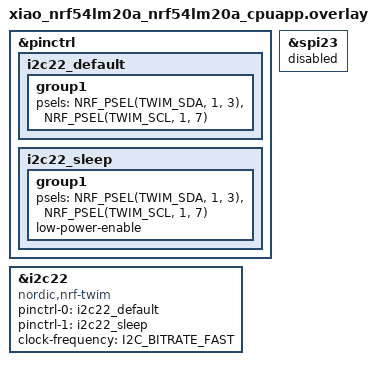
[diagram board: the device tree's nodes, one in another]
/*
 * BMP280 Sensor Demo - Device Tree Overlay for XIAO nRF54LM20A
 * Default I2C Address: 0x76
 * I2C Bus: i2c22 (SDA: P1.3, SCL: P1.7)
 *
 * If your module SDO pin is pulled high, change reg to <0x77>.
 */

&pinctrl {
	i2c22_default: i2c22_default {
		group1 {
			psels = <NRF_PSEL(TWIM_SDA, 1, 3)>,
				<NRF_PSEL(TWIM_SCL, 1, 7)>;
		};
	};

	i2c22_sleep: i2c22_sleep {
		group1 {
			psels = <NRF_PSEL(TWIM_SDA, 1, 3)>,
				<NRF_PSEL(TWIM_SCL, 1, 7)>;
			low-power-enable;
		};
	};
};

&i2c22 {
	compatible = "nordic,nrf-twim";
	status = "okay";
	pinctrl-0 = <&i2c22_default>;
	pinctrl-1 = <&i2c22_sleep>;
	pinctrl-names = "default", "sleep";
	/* Initial speed; overridden at runtime by i2c_configure() in main.c */
	clock-frequency = <I2C_BITRATE_FAST>;
};

&spi23 {
	status = "disabled";
};
